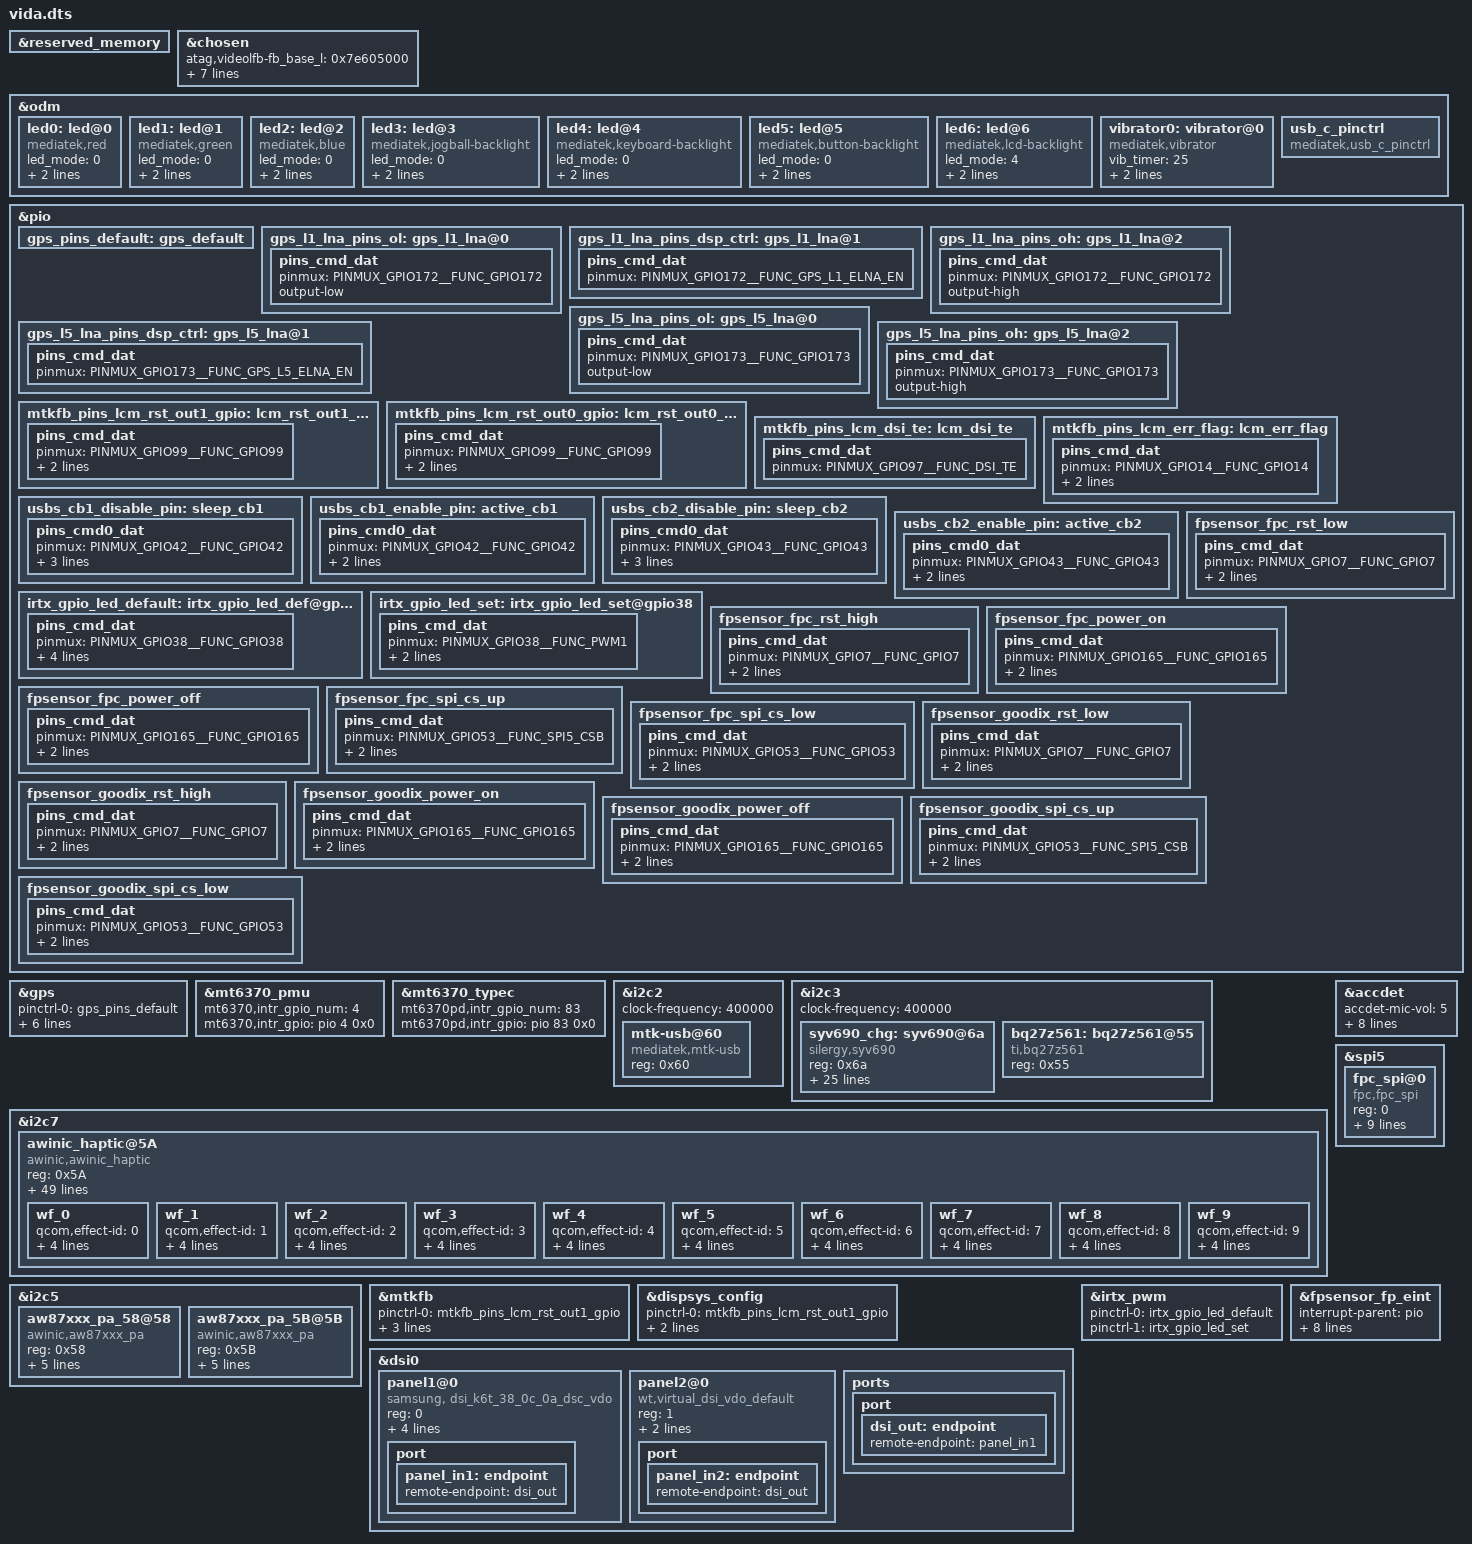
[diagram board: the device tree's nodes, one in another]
/*
 * Copyright (C) 2015 MediaTek Inc.
 *
 * This program is free software: you can redistribute it and/or modify
 * it under the terms of the GNU General Public License version 2 as
 * published by the Free Software Foundation.
 *
 * This program is distributed in the hope that it will be useful,
 * but WITHOUT ANY WARRANTY; without even the implied warranty of
 * MERCHANTABILITY or FITNESS FOR A PARTICULAR PURPOSE. See the
 * GNU General Public License for more details.
 */
/dts-v1/;
/plugin/;
#include <dt-bindings/interrupt-controller/irq.h>
#include <dt-bindings/interrupt-controller/arm-gic.h>
#include <dt-bindings/pinctrl/mt6781-pinfunc.h>

&reserved_memory {
};

/* chosen */
&chosen {
	/* fpga may has no lk, we need to specify display info here */
	/* fb buffer is reserved using this dts by memory node above */
	atag,videolfb-fb_base_l = <0x7e605000>;
	atag,videolfb-fb_base_h = <0x0>;
	atag,videolfb-islcmfound = <1>;
	atag,videolfb-islcm_inited = <0>;
	atag,videolfb-fps= <6000>;
	atag,videolfb-vramSize= <0x017e8000>;
	atag,videolfb-lcmname=
		"nt35695_fhd_dsi_cmd_truly_rt5081_drv";
};

&odm {
	led0:led@0 {
		compatible = "mediatek,red";
		led_mode = <0>;
		data = <1>;
		pwm_config = <0 0 0 0 0>;
	};
	led1:led@1 {
		compatible = "mediatek,green";
		led_mode = <0>;
		data = <1>;
		pwm_config = <0 0 0 0 0>;
	};
	led2:led@2 {
		compatible = "mediatek,blue";
		led_mode = <0>;
		data = <1>;
		pwm_config = <0 0 0 0 0>;
	};
	led3:led@3 {
		compatible = "mediatek,jogball-backlight";
		led_mode = <0>;
		data = <1>;
		pwm_config = <0 0 0 0 0>;
	};
	led4:led@4 {
		compatible = "mediatek,keyboard-backlight";
		led_mode = <0>;
		data = <1>;
		pwm_config = <0 0 0 0 0>;
	};
	led5:led@5 {
		compatible = "mediatek,button-backlight";
		led_mode = <0>;
		data = <1>;
		pwm_config = <0 0 0 0 0>;
	};
	led6:led@6 {
		compatible = "mediatek,lcd-backlight";
		led_mode = <4>;
		data = <1>;
		pwm_config = <0 1 0 0 0>;
	};
	vibrator0:vibrator@0 {
		compatible = "mediatek,vibrator";
		vib_timer = <25>;
		vib_limit = <9>;
		vib_vol= <9>;
	};

	usb_c_pinctrl:usb_c_pinctrl {
		compatible = "mediatek,usb_c_pinctrl";
	};
};

/* GPS GPIO standardization start */
&pio {
	gps_pins_default: gps_default {
	};

	gps_l1_lna_pins_ol: gps_l1_lna@0 {
		pins_cmd_dat {
			pinmux = <PINMUX_GPIO172__FUNC_GPIO172>;
			output-low;
		};
	};
	gps_l1_lna_pins_dsp_ctrl: gps_l1_lna@1 {
		pins_cmd_dat {
			pinmux = <PINMUX_GPIO172__FUNC_GPS_L1_ELNA_EN>;
		};
	};
	gps_l1_lna_pins_oh: gps_l1_lna@2 {
		pins_cmd_dat {
			pinmux = <PINMUX_GPIO172__FUNC_GPIO172>;
			output-high;
		};
	};

	gps_l5_lna_pins_ol: gps_l5_lna@0 {
		pins_cmd_dat {
			pinmux = <PINMUX_GPIO173__FUNC_GPIO173>;
			output-low;
		};
	};
	gps_l5_lna_pins_dsp_ctrl: gps_l5_lna@1 {
		pins_cmd_dat {
			pinmux = <PINMUX_GPIO173__FUNC_GPS_L5_ELNA_EN>;
		};
	};
	gps_l5_lna_pins_oh: gps_l5_lna@2 {
		pins_cmd_dat {
			pinmux = <PINMUX_GPIO173__FUNC_GPIO173>;
			output-high;
		};
	};
};

&gps {
	pinctrl-names = "default",
		"gps_l1_lna_disable",
		"gps_l1_lna_dsp_ctrl",
		"gps_l1_lna_enable",
		"gps_l5_lna_disable",
		"gps_l5_lna_dsp_ctrl",
		"gps_l5_lna_enable";
	pinctrl-0 = <&gps_pins_default>;
	pinctrl-1 = <&gps_l1_lna_pins_ol>;
	pinctrl-2 = <&gps_l1_lna_pins_dsp_ctrl>;
	pinctrl-3 = <&gps_l1_lna_pins_oh>;
	pinctrl-4 = <&gps_l5_lna_pins_ol>;
	pinctrl-5 = <&gps_l5_lna_pins_dsp_ctrl>;
	pinctrl-6 = <&gps_l5_lna_pins_oh>;
	status = "okay";
};
/* GPS GPIO standardization end */

&mt6370_pmu {
	mt6370,intr_gpio_num = <4>; /* direct defined GPIO num */
	mt6370,intr_gpio = <&pio 4 0x0>;
};

&mt6370_typec {
	mt6370pd,intr_gpio_num = <83>; /* direct defined GPIO num */
	mt6370pd,intr_gpio = <&pio 83 0x0>;
};

&i2c2 {
	clock-frequency = <400000>;
	mtk-usb@60 {
		compatible = "mediatek,mtk-usb";
		reg = <0x60>;
		status = "okay";
	};
};

&i2c3 {
	clock-frequency = <400000>;
	syv690_chg:syv690@6a {
		compatible = "silergy,syv690";
		reg = <0x6a>;
		syv690,intr_gpio = <&pio 11 0x0>;
		syv690,intr_gpio_num = <11>;
		charger_name = "primary_chg";
		silergy,syv690,current-sensor-mohm = <55>;
		silergy,syv690,usb-vreg = <4450>;
		silergy,syv690,usb-ichg = <1550>;
		silergy,syv690,usb-ilim = <1500>;
		silergy,syv690,usb-vlim = <4600>;/*vindpm threshold*/
		silergy,syv690,vbatlow-volt = <3500>;
		silergy,syv690,termination-current = <260>;
		silergy,syv690,safety-max-charge-current = <3000>;
		silergy,syv690,safety-max-charge-voltage = <4450>;
		silergy,syv690,boost-voltage = <5300>;
		silergy,syv690,boost-current = <1200>;
		usb_switch_cb1_gpio_num = <42>;
		usb_switch_cb1_gpio = <&pio 42 0x0>;	
		usb_switch_cb2_gpio_num = <43>;	
		usb_switch_cb2_gpio = <&pio 43 0x0>;
		otg_en_gpio_num = <79>;	
		otg_en_gpio = <&pio 79 0x0>;
		pinctrl-names = "active_cb1", "sleep_cb1","active_cb2", "sleep_cb2";
		pinctrl-0 = <&usbs_cb1_enable_pin>;
		pinctrl-1 = <&usbs_cb1_disable_pin>;
		pinctrl-2 = <&usbs_cb2_enable_pin>;
		pinctrl-3 = <&usbs_cb2_disable_pin>;	
		charger = <&syv690_chg>;		
		status = "okay";
	};
	bq27z561:bq27z561@55 {
		compatible = "ti,bq27z561";
		reg = <0x55>;
	};
};

&i2c7 {
	awinic_haptic@5A{
		compatible = "awinic,awinic_haptic";
		reg = < 0x5A >;
		aw862xx_i2c_addr = < 0x58 >;
		reset-gpio = <&pio 23 0>;
		irq-gpio = <&pio 10 0>;
		/*---------------------aw8624_dts_info---------------------*/
		aw8624_vib_f0_pre = < 2050 >;
		aw8624_vib_f0_cali_percen = < 7 >;
		aw8624_vib_cont_drv_lev = < 106 >;
		aw8624_vib_cont_drv_lvl_ov = < 155 >;
		aw8624_vib_cont_td = < 0xF06C >;
		aw8624_vib_cont_zc_thr = < 0x08F8 >;
		aw8624_vib_cont_num_brk = < 3 >;
		aw8624_vib_f0_coeff = < 260 >; /*Don't modify it*/
		aw8624_vib_duration_time = < 15 60 0 0 0 >;
		aw8624_vib_brake_ram_config = < 1 1 90 60 20 3 1 3 1 1 90 60 30 5 1 3 0 0 50 40 25 0 5 3 >;
		aw8624_vib_brake_cont_config = < 1 1 90 42 20 5 2 2 0 0 0 0 0 0 0 0 0 0 0 0 0 0 0 0 >;
		aw8624_vib_f0_trace_parameter = < 9 5 1 15 >;
		aw8624_vib_bemf_config = < 0 8 3 0xf8 >;
		aw8624_vib_sw_brake = < 0x2c >;
		aw8624_vib_wavseq = < 0 1 1 2 0 0 0 0 0 0 0 0 0 0 0 0 >; /*wavseq1-seq8 0x07-0x0E*/
		aw8624_vib_wavloop = < 0 6 1 15 0 0 0 0 0 0>;/*loop1-mainloog 0x0f-0x13*/
		aw8624_vib_td_brake = < 42720 42720 42720 >; /*level0 level1 level2*/
		aw8624_vib_tset = < 0x11 >;
		aw8624_vib_func_parameter1 = < 1 >;
		aw8624_vib_gain_flag = < 1 >;
		aw8624_vib_r_spare = < 0x68 >;
		aw8624_vib_bstdbg = < 0x30 0xeb 0xd4 0 0 0 >;
		/*---------------------aw8622x_dts_info---------------------*/
		aw8622x_vib_mode = < 0 >; /* mode: RAM mode->0; CONT mode->1 */
		aw8622x_vib_f0_pre = < 2050 >;
		aw8622x_vib_f0_cali_percen = < 7 >;
		aw8622x_vib_cont_drv1_lvl = < 0x7F >;
		aw8622x_vib_cont_drv2_lvl = < 0x36 >;
		aw8622x_vib_cont_brk_time = < 0x06 >;
		aw8622x_vib_cont_tset = < 0x06 >;
		aw8622x_vib_cont_bemf_set = < 0x02 >;
		aw8622x_vib_cont_drv_width = < 0x6A >;
		aw8622x_vib_cont_wait_num = < 0x06 >;
		aw8622x_vib_cont_brk_gain = < 0x08 >;
		aw8622x_vib_cont_drv1_time = < 0x04 >;
		aw8622x_vib_cont_drv2_time = < 0x14 >;
		aw8622x_vib_cont_track_margin = < 0x12 >;
		aw8622x_vib_sine_array = < 0x05 0xB2 0xFF 0xEF >; /* SIN_H SIN_L COS_H COS_L*/
		aw8622x_vib_d2s_gain = < 0x05 >;
		aw8622x_vib_prctmode = < 0x2D 0x3E 0x3F >;
		/*---------------------common_dts_info---------------------*/
		vib_effect_id_boundary = < 10 >;
		vib_effect_max = < 170 >;
		vib_rtp_time = < 20 20 20 20 20 20 20 20 20 30
				 40 50 60 70 80 90 100 110 120 130
				 140 150 160 170 180 190 200 210 220 230
				 240 250 260 270 280 290 300 310 320 330
				 20 20 20 20 20 20 20 20 20 20
				 20 20 20 20 20 20 20 20 20 20
				 20 20 20 20 20 20 20 20 20 20
				 20 20 20 20 20 20 20 20 20 20
				 20 20 20 20 20 20 20 20 20 20
				 20 20 20 20 20 20 20 20 20 20
				 20 20 20 20 20 20 20 20 20 20
				 20 20 20 20 20 20 20 20 20 20
				 20 20 20 20 20 20 20 20 20 20
				 20 20 20 20 20 20 20 20 20 20
				 20 20 20 20 20 20 20 20 20 20
				 20 20 20 20 20 20 20 20 20 20
				 20 20 20 20 20 20 20 20 20 20
				 20 20 20 20 20 >;
		status = "okay";
		wf_0 {
			//CLICK
			qcom,effect-id = <0>;
			qcom,wf-vmax-mv = <3600>;
			qcom,wf-pattern = [3e 3e];
			qcom,wf-brake-pattern = [02 01 00 00];
			qcom,wf-play-rate-us = <20000>;
		};
		wf_1 {
			//DOUBLE CLICK
			qcom,effect-id = <1>;
			qcom,wf-vmax-mv = <3600>;
			qcom,wf-pattern = [7e 3e];
			qcom,wf-brake-pattern = [03 01 00 00];
			qcom,wf-play-rate-us = <20000>;
		};
		wf_2 {
			//TICK
			qcom,effect-id = <2>;
			qcom,wf-vmax-mv = <3600>;
			qcom,wf-pattern = [7e 3e];
			qcom,wf-brake-pattern = [02 01 00 00];
			qcom,wf-play-rate-us = <20000>;
		};
		wf_3 {
			//THUD
			qcom,effect-id = <3>;
			qcom,wf-vmax-mv = <3600>;
			qcom,wf-pattern = [3e 3e];
			qcom,wf-brake-pattern = [02 01 00 00];
			qcom,wf-play-rate-us = <20000>;
		};
		wf_4 {
			//POP
			qcom,effect-id = <4>;
			qcom,wf-vmax-mv = <3600>;
			qcom,wf-pattern = [3e 3e];
			qcom,wf-brake-pattern = [02 01 00 00];
			qcom,wf-play-rate-us = <28000>;
		};
		wf_5 {
			//HEAVY CLICK
			qcom,effect-id = <5>;
			qcom,wf-vmax-mv = <3600>;
			qcom,wf-pattern = [7e 7e 7e];
			qcom,wf-brake-pattern = [03 03 01 00];
			qcom,wf-play-rate-us = <20000>;
		};
		wf_6 {
			//id 6
			qcom,effect-id = <6>;
			qcom,wf-vmax-mv = <3600>;
			qcom,wf-pattern = [3e 3e];
			qcom,wf-brake-pattern = [02 01 00 00];
			qcom,wf-play-rate-us = <20000>;
		};
		wf_7 {
			//id 7
			qcom,effect-id = <7>;
			qcom,wf-vmax-mv = <3600>;
			qcom,wf-pattern = [3e 3e];
			qcom,wf-brake-pattern = [02 01 00 00];
			qcom,wf-play-rate-us = <20000>;
		};
		wf_8 {
			//id 8
			qcom,effect-id = <8>;
			qcom,wf-vmax-mv = <3600>;
			qcom,wf-pattern = [3e 3e];
			qcom,wf-brake-pattern = [02 01 00 00];
			qcom,wf-play-rate-us = <20000>;
		};
		wf_9 {
			//id 9
			qcom,effect-id = <9>;
			qcom,wf-vmax-mv = <3600>;
			qcom,wf-pattern = [3e 3e];
			qcom,wf-brake-pattern = [02 01 00 00];
			qcom,wf-play-rate-us = <20000>;
		};
	};
};

/* accdet start */
&accdet {
	/* accdet micbias voltage: 0x07,2.7v;0x05,2.5v;0x02,1.9v */
	accdet-mic-vol = <5>;
	headset-mode-setting = <0x500 0x500 1 0x1f0 0x800 0x800 0x20 0x44>;
	accdet-plugout-debounce = <1>;
	/*1:ACC mode, 2:low cost without in bias, 6:low cost with in bias*/
	accdet-mic-mode = <1>;
	/* eint_level_trigger: 8,LEVEL_LOW(DEF) ;4,LV_HIGH;others,LV_LOW */
	headset-eint-level-pol = <8>;
	/*0--MD_MAX--UP_MAX--DW_MAX*/
	headset-three-key-threshold = <0 80 220 400>;
	headset-three-key-threshold-CDD = <0 121 192 600>;
	/*0--MD_MAX--VOICE_MAX--UP_MAX--DW_MAX*/
	headset-four-key-threshold = <0 58 121 192 400>;
	status = "okay";
};
/* accdet end */

&i2c5 {
/* AWINIC AW87XXX Smart K PA */
       aw87xxx_pa_58@58 {
               compatible = "awinic,aw87xxx_pa";
               reg = <0x58>;
               reset-gpio = <&pio 19 0>;
               monitor-flag = <1>;
               pa-channel = < 0 >;
               monitor-timer-val = <3000>;
               monitor-timer-count-max = <5>;
               status = "okay";
       };

       aw87xxx_pa_5B@5B {
               compatible = "awinic,aw87xxx_pa";
               reg = <0x5B>;
               reset-gpio = <&pio 25 0>;
               monitor-flag = <1>;
               pa-channel = < 1 >;
               monitor-timer-val = <3000>;
               monitor-timer-count-max = <5>;
               status = "okay";
       };
/* AWINIC AW87XXX Smart K PA End */
};

#ifndef CONFIG_FPGA_EARLY_PORTING
&pio {
	mtkfb_pins_lcm_rst_out1_gpio: lcm_rst_out1_gpio {
		pins_cmd_dat {
			pinmux = <PINMUX_GPIO99__FUNC_GPIO99>;
			slew-rate = <1>;
			output-high;
		};
	};

	mtkfb_pins_lcm_rst_out0_gpio: lcm_rst_out0_gpio {
		pins_cmd_dat {
			pinmux = <PINMUX_GPIO99__FUNC_GPIO99>;
			slew-rate = <1>;
			output-low;
		};
	};
	mtkfb_pins_lcm_dsi_te: lcm_dsi_te {
		pins_cmd_dat {
			pinmux = <PINMUX_GPIO97__FUNC_DSI_TE>;
		};
	};

	mtkfb_pins_lcm_err_flag: lcm_err_flag {
		pins_cmd_dat {
			pinmux = <PINMUX_GPIO14__FUNC_GPIO14>;
			slew-rate = <0>;
			bias-disable;
		};
	};

	usbs_cb1_disable_pin: sleep_cb1 {
		pins_cmd0_dat {
			pinmux = <PINMUX_GPIO42__FUNC_GPIO42>;
			drive-strength = <6>;
			input-enable;
			bias-disable;
		};
	};

	usbs_cb1_enable_pin: active_cb1 {
		pins_cmd0_dat {
			pinmux = <PINMUX_GPIO42__FUNC_GPIO42>;
			drive-strength = <6>;
			bias-pull-up;
		};
	};

	usbs_cb2_disable_pin: sleep_cb2 {
		pins_cmd0_dat {
			pinmux = <PINMUX_GPIO43__FUNC_GPIO43>;
			drive-strength = <6>;
			input-enable;
			bias-disable;
		};
	};

	usbs_cb2_enable_pin: active_cb2 {
		pins_cmd0_dat {
			pinmux = <PINMUX_GPIO43__FUNC_GPIO43>;
			drive-strength = <6>;
			bias-pull-up;
		};
	};	
	
};

&mtkfb {
	pinctrl-names = "lcm_rst_out1_gpio", "lcm_rst_out0_gpio",
		"mode_te_te", "err_flag_init";
	pinctrl-0 = <&mtkfb_pins_lcm_rst_out1_gpio>;
	pinctrl-1 = <&mtkfb_pins_lcm_rst_out0_gpio>;
	pinctrl-2 = <&mtkfb_pins_lcm_dsi_te>;
	pinctrl-3 = <&mtkfb_pins_lcm_err_flag>;
	status = "okay";
};

&dispsys_config {
	pinctrl-names =
		"lcm_rst_out1_gpio", "lcm_rst_out0_gpio",
		"mode_te_te";
	pinctrl-0 = <&mtkfb_pins_lcm_rst_out1_gpio>;
	pinctrl-1 = <&mtkfb_pins_lcm_rst_out0_gpio>;
	pinctrl-2 = <&mtkfb_pins_lcm_dsi_te>;
	status = "okay";
};

&dsi0 {
	status = "okay";
	#address-cells = <1>;
	#size-cells = <0>;
	panel1@0 {
		compatible = "samsung, dsi_k6t_38_0c_0a_dsc_vdo";
		reg = <0>;
		reset-gpios = <&pio 99 0>;
		bias-gpios = <&pio 167 0>;
		vio1v8-gpios = <&pio 75 0>;
		mi,esd-err-irq-gpio = <&pio 14 0x2002>;
		pinctrl-names = "default";
		port {
			panel_in1: endpoint {
				remote-endpoint = <&dsi_out>;
			};
		};
	};
	panel2@0 {
		compatible = "wt,virtual_dsi_vdo_default";
		reg = <1>;
		reset-gpios = <&pio 99 0>;
		bias-gpios = <&pio 167 0>;
		pinctrl-names = "default";
		port {
			panel_in2: endpoint {
				remote-endpoint = <&dsi_out>;
			};
		};
	};
	ports {
		port {
			dsi_out: endpoint {
				remote-endpoint = <&panel_in1>;
			};
		};
	};
};

/* IRTX GPIO Start */
&irtx_pwm {
	pinctrl-names = "irtx_gpio_led_default", "irtx_gpio_led_set";
	pinctrl-0 = <&irtx_gpio_led_default>;
	pinctrl-1 = <&irtx_gpio_led_set>;
	status = "okay";
};
&pio {
	/* IRTX GPIO Settings -Start */
	/* default: GPIO0, output, high */
	irtx_gpio_led_default:irtx_gpio_led_def@gpio38 {
		pins_cmd_dat {
			pinmux = <PINMUX_GPIO38__FUNC_GPIO38>;
			slew-rate = <1>;
			bias-disable;
			output-low;
			input-schmitt-enable = <0>;
		};
	};

	irtx_gpio_led_set:irtx_gpio_led_set@gpio38 {
		pins_cmd_dat {
			pinmux = <PINMUX_GPIO38__FUNC_PWM1>;
			slew-rate = <1>;
			output-high;
		};
	};
}; /* IRTX GPIO Settings -End */

#endif

/*fingerprint start*/
&pio {
	fpsensor_fpc_rst_low: fpsensor_fpc_rst_low {
		pins_cmd_dat {
			pinmux = <PINMUX_GPIO7__FUNC_GPIO7>;
			slew-rate = <1>;
			output-low;
		};
	};

	fpsensor_fpc_rst_high: fpsensor_fpc_rst_high {
		pins_cmd_dat {
			pinmux = <PINMUX_GPIO7__FUNC_GPIO7>;
			slew-rate = <1>;
			output-high;
		};
	};
	
	fpsensor_fpc_power_on: fpsensor_fpc_power_on {
		pins_cmd_dat {
			pinmux = <PINMUX_GPIO165__FUNC_GPIO165>;
			slew-rate = <1>;
			output-high;
		};
	};
	
	fpsensor_fpc_power_off: fpsensor_fpc_power_off {
		pins_cmd_dat {
			pinmux = <PINMUX_GPIO165__FUNC_GPIO165>;
			slew-rate = <1>;
			output-low;
		};
	};
	
	fpsensor_fpc_spi_cs_up: fpsensor_fpc_spi_cs_up {
		pins_cmd_dat {
			pinmux = <PINMUX_GPIO53__FUNC_SPI5_CSB>;
			slew-rate = <1>;
			bias-pull-up;
		};
	};
	
	fpsensor_fpc_spi_cs_low: fpsensor_fpc_spi_cs_low {
		pins_cmd_dat {
			pinmux = <PINMUX_GPIO53__FUNC_GPIO53>;
			slew-rate = <1>;
			output-low;
		};
	};
};
&pio {
	fpsensor_goodix_rst_low: fpsensor_goodix_rst_low {
		pins_cmd_dat {
			pinmux = <PINMUX_GPIO7__FUNC_GPIO7>;
			slew-rate = <1>;
			output-low;
		};
	};

	fpsensor_goodix_rst_high: fpsensor_goodix_rst_high {
		pins_cmd_dat {
			pinmux = <PINMUX_GPIO7__FUNC_GPIO7>;
			slew-rate = <1>;
			output-high;
		};
	};
	
	fpsensor_goodix_power_on: fpsensor_goodix_power_on {
		pins_cmd_dat {
			pinmux = <PINMUX_GPIO165__FUNC_GPIO165>;
			slew-rate = <1>;
			output-high;
		};
	};
	
	fpsensor_goodix_power_off: fpsensor_goodix_power_off {
		pins_cmd_dat {
			pinmux = <PINMUX_GPIO165__FUNC_GPIO165>;
			slew-rate = <1>;
			output-low;
		};
	};
	
	fpsensor_goodix_spi_cs_up: fpsensor_goodix_spi_cs_up {
		pins_cmd_dat {
			pinmux = <PINMUX_GPIO53__FUNC_SPI5_CSB>;
			slew-rate = <1>;
			bias-pull-up;
		};
	};
	
	fpsensor_goodix_spi_cs_low: fpsensor_goodix_spi_cs_low {
		pins_cmd_dat {
			pinmux = <PINMUX_GPIO53__FUNC_GPIO53>;
			slew-rate = <1>;
			output-low;
		};
	};
};

&spi5 {
	fpc_spi@0 {
		compatible = "fpc,fpc_spi";
		reg = <0>;
		fpc,enable-wakeup;
		spi-max-frequency = <10000000>;
		netlink-event = <31>;
		pinctrl-names = "fpsensor_fpc_rst_low", "fpsensor_fpc_rst_high","fpsensor_fpc_power_on","fpsensor_fpc_power_off","fpsensor_fpc_spi_cs_up","fpsensor_fpc_spi_cs_low";
		pinctrl-0 = <&fpsensor_fpc_rst_low>;
		pinctrl-1 = <&fpsensor_fpc_rst_high>;
		pinctrl-2 = <&fpsensor_fpc_power_on>;
		pinctrl-3 = <&fpsensor_fpc_power_off>;
	    pinctrl-4 = <&fpsensor_fpc_spi_cs_up>;
	    pinctrl-5 = <&fpsensor_fpc_spi_cs_low>;
		status = "okay";
	};
};

&fpsensor_fp_eint {
	interrupt-parent = <&pio>;
	interrupts = <1 IRQ_TYPE_EDGE_RISING 1 0>;
	int-gpios = <&pio 1 0>;
	pinctrl-names = "fpsensor_goodix_rst_low", "fpsensor_goodix_rst_high","fpsensor_goodix_power_on","fpsensor_goodix_power_off","fpsensor_goodix_spi_cs_up","fpsensor_goodix_spi_cs_low";
	pinctrl-0 = <&fpsensor_goodix_rst_low>;
	pinctrl-1 = <&fpsensor_goodix_rst_high>;
	pinctrl-2 = <&fpsensor_goodix_power_on>;
	pinctrl-3 = <&fpsensor_goodix_power_off>;
	pinctrl-4 = <&fpsensor_goodix_spi_cs_up>;
	pinctrl-5 = <&fpsensor_goodix_spi_cs_low>;
	status = "okay";
};
/*fingerprint end*/
#include <vida/cust.dtsi>
#include "mediatek/cust_mt6781_camera.dtsi"
#include "mediatek/cust_mt6781_touch_gt9896_1080x2400.dtsi"
/*End of this file, DO NOT ADD ANYTHING HERE*/
